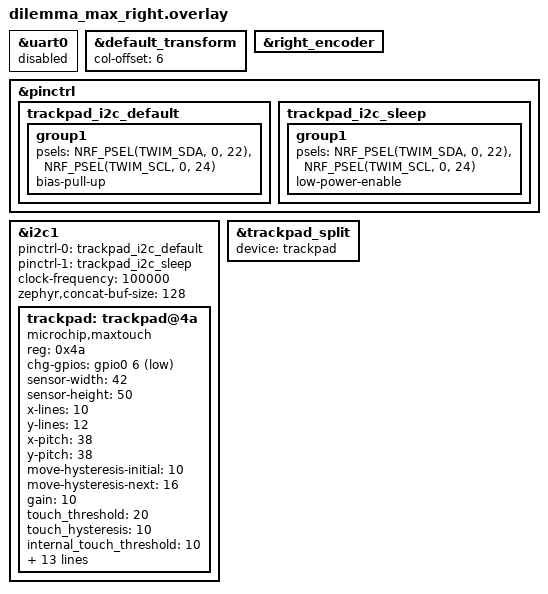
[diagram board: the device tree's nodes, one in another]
// Dilemma Max - Right Side

#include "dilemma_max.dtsi"

// Disable UART0 (uses P0.06 as TX) to free pin for CHG interrupt
&uart0 {
    status = "disabled";
};

&default_transform {
    col-offset = <6>;
};

&right_encoder {
    status = "okay";
};

// I2C0 ist auf der rechten Seite frei (Nice!View nur links)
// SDA=P0.22(pin4), SCL=P0.24(pin5) - nRF52840 routing matrix erlaubt beliebige GPIOs
&pinctrl {
    trackpad_i2c_default: trackpad_i2c_default {
        group1 {
            psels = <NRF_PSEL(TWIM_SDA, 0, 22)>,
                    <NRF_PSEL(TWIM_SCL, 0, 24)>;
            bias-pull-up;
        };
    };
    trackpad_i2c_sleep: trackpad_i2c_sleep {
        group1 {
            psels = <NRF_PSEL(TWIM_SDA, 0, 22)>,
                    <NRF_PSEL(TWIM_SCL, 0, 24)>;
            low-power-enable;
        };
    };
};

&i2c1 {
    status = "okay";
    pinctrl-0 = <&trackpad_i2c_default>;
    pinctrl-1 = <&trackpad_i2c_sleep>;
    pinctrl-names = "default", "sleep";
    clock-frequency = <100000>;
    // maxtouch-Treiber schreibt Registeradresse + Config-Block als zwei Messages ohne STOP,
    // der TWIM-Treiber kopiert das in einen internen Puffer (Default 16 Bytes, zu klein fuer T100)
    zephyr,concat-buf-size = <128>;

    trackpad: trackpad@4a {
        compatible = "microchip,maxtouch";
        reg = <0x4a>;
        chg-gpios = <&gpio0 6 GPIO_ACTIVE_LOW>;
        // Procyon 42x50 (George Norton). Werte fuer Matrix, Pitch, Hysterese, Entprellung,
        // T56 und T80 aus dessen QMK-Treiber (drivers/sensors/procyon.h, Zweig
        // multitouch_experiment), der genau dieses Pad fuer den Dilemma 4x6 konfiguriert.
        sensor-width = <42>;
        sensor-height = <50>;
        x-lines = <10>;              // Pad belegt X0-X9 ...
        y-lines = <12>;              // ... und Y0-Y11 (Chip-Maximum 14x24)
        x-pitch = <38>;              // 3.8 mm Raster
        y-pitch = <38>;
        // Kompletter Satz aus dem QMK-Treiber des Autors fuer das Procyon 42x50
        // (drivers/sensors/procyon.h + maxtouch.c). Wichtig: diese Werte gehoeren zusammen --
        // Schwelle 20 funktioniert nur mit charge_time 1, gain 10 und beiden Messverfahren.
        move-hysteresis-initial = <10>;
        move-hysteresis-next = <16>;
        gain = <10>;
        touch_threshold = <20>;
        touch_hysteresis = <10>;
        internal_touch_threshold = <10>;
        internal_touch_hysteresis = <5>;
        charge_time = <1>;
        allowed_measurement_types = <3>;
        active_syncs_per_x = <0>;
        idle_syncs_per_x = <0>;
        confthr = <5>;                       // Touch-Entprellung
        // Stand vor dem Versuch mit 1/2: der niedrigere Wert hat das Scrollen verschlechtert
        merge-threshold = <2>;
        merge-hysteresis = <5>;
        // Auslaufendes Scrollen nach dem Abheben
        scroll-momentum;
        shieldless-enable;                   // T56 Rauschunterdrueckung
        retransmission_compensation_disable; // T80 aus
        // Chip misst im aktiven Zustand freilaufend statt alle 10 ms (255 = free run)
        active-acq-time-ms = <255>;
        // ... und bleibt wie im QMK-Treiber 10 s aktiv, bevor er in den Ruhemodus faellt
        // (Einheit 200 ms; 2 s waren zu kurz, jeder Idle-Wechsel stoert die Baseline)
        active-to-idle-timeout-ms = <50>;
        // Diagnose: T37-Rohdaten ins Log (Referenzen einmal, Deltas alle 3s)
        // diag-dump;
        // swap-xy war falsch: Finger links-rechts bewegte den Cursor oben-unten
        // swap-xy;
    };
};

// Trackpad-Events an den Input-Split haengen (Peripheral -> Central)
&trackpad_split {
    device = <&trackpad>;
};
